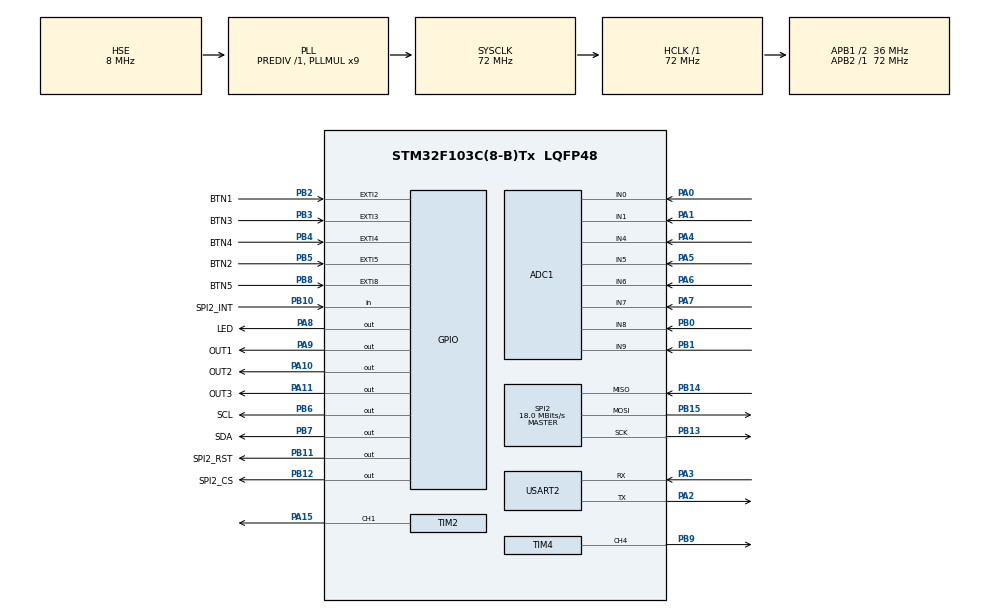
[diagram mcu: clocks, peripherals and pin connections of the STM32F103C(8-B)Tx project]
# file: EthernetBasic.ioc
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ADC1.Channel-0\#ChannelRegularConversion=ADC_CHANNEL_0
ADC1.Channel-1\#ChannelRegularConversion=ADC_CHANNEL_1
ADC1.Channel-2\#ChannelRegularConversion=ADC_CHANNEL_4
ADC1.Channel-3\#ChannelRegularConversion=ADC_CHANNEL_5
ADC1.Channel-4\#ChannelRegularConversion=ADC_CHANNEL_6
ADC1.Channel-5\#ChannelRegularConversion=ADC_CHANNEL_7
ADC1.Channel-6\#ChannelRegularConversion=ADC_CHANNEL_8
ADC1.Channel-7\#ChannelRegularConversion=ADC_CHANNEL_9
ADC1.ContinuousConvMode=DISABLE
ADC1.ExternalTrigConv=ADC_EXTERNALTRIGCONV_T3_TRGO
ADC1.NbrOfConversion=8
ADC1.NbrOfConversionFlag=1
ADC1.Rank-0\#ChannelRegularConversion=1
ADC1.Rank-1\#ChannelRegularConversion=2
ADC1.Rank-2\#ChannelRegularConversion=3
ADC1.Rank-3\#ChannelRegularConversion=4
ADC1.Rank-4\#ChannelRegularConversion=5
ADC1.Rank-5\#ChannelRegularConversion=6
ADC1.Rank-6\#ChannelRegularConversion=7
ADC1.Rank-7\#ChannelRegularConversion=8
ADC1.SamplingTime-0\#ChannelRegularConversion=ADC_SAMPLETIME_7CYCLES_5
ADC1.SamplingTime-1\#ChannelRegularConversion=ADC_SAMPLETIME_7CYCLES_5
ADC1.SamplingTime-2\#ChannelRegularConversion=ADC_SAMPLETIME_7CYCLES_5
ADC1.SamplingTime-3\#ChannelRegularConversion=ADC_SAMPLETIME_7CYCLES_5
ADC1.SamplingTime-4\#ChannelRegularConversion=ADC_SAMPLETIME_7CYCLES_5
ADC1.SamplingTime-5\#ChannelRegularConversion=ADC_SAMPLETIME_7CYCLES_5
ADC1.SamplingTime-6\#ChannelRegularConversion=ADC_SAMPLETIME_7CYCLES_5
ADC1.SamplingTime-7\#ChannelRegularConversion=ADC_SAMPLETIME_7CYCLES_5
ADC1.master=1
Dma.ADC1.0.Direction=DMA_PERIPH_TO_MEMORY
Dma.ADC1.0.Instance=DMA1_Channel1
Dma.ADC1.0.MemDataAlignment=DMA_MDATAALIGN_HALFWORD
Dma.ADC1.0.MemInc=DMA_MINC_ENABLE
Dma.ADC1.0.Mode=DMA_CIRCULAR
Dma.ADC1.0.PeriphDataAlignment=DMA_PDATAALIGN_HALFWORD
Dma.ADC1.0.PeriphInc=DMA_PINC_DISABLE
Dma.ADC1.0.Priority=DMA_PRIORITY_LOW
Dma.Request0=ADC1
Mcu.Family=STM32F1
Mcu.Name=STM32F103C(8-B)Tx
Mcu.Package=LQFP48
NVIC.DMA1_Channel1_IRQn=true\:0\:0\:false\:false\:true\:false\:true\:true
NVIC.EXTI2_IRQn=true\:0\:0\:false\:false\:true\:true\:true\:true
NVIC.EXTI3_IRQn=true\:0\:0\:false\:false\:true\:true\:true\:true
NVIC.EXTI4_IRQn=true\:0\:0\:false\:false\:true\:true\:true\:true
NVIC.EXTI9_5_IRQn=true\:0\:0\:false\:false\:true\:true\:true\:true
NVIC.PriorityGroup=NVIC_PRIORITYGROUP_4
PA0-WKUP.Signal=ADCx_IN0
PA1.Signal=ADCx_IN1
PA10.GPIO_Label=OUT2
PA10.Signal=GPIO_Output
PA11.GPIO_Label=OUT3
PA11.Signal=GPIO_Output
PA13.Mode=Serial_Wire
PA13.Signal=SYS_JTMS-SWDIO
PA14.Mode=Serial_Wire
PA14.Signal=SYS_JTCK-SWCLK
PA15.Signal=S_TIM2_CH1_ETR
PA2.Mode=Asynchronous
PA2.Signal=USART2_TX
PA3.Mode=Asynchronous
PA3.Signal=USART2_RX
PA4.Signal=ADCx_IN4
PA5.Signal=ADCx_IN5
PA6.Signal=ADCx_IN6
PA7.Signal=ADCx_IN7
PA8.GPIO_Label=LED
PA8.Signal=GPIO_Output
PA9.GPIO_Label=OUT1
PA9.Signal=GPIO_Output
PB0.Signal=ADCx_IN8
PB1.Signal=ADCx_IN9
PB10.GPIO_Label=SPI2_INT
PB10.GPIO_PuPd=GPIO_PULLUP
PB10.Signal=GPIO_Input
PB11.GPIO_Label=SPI2_RST
PB11.GPIO_PuPd=GPIO_PULLUP
PB11.GPIO_Speed=GPIO_SPEED_FREQ_HIGH
PB11.Signal=GPIO_Output
PB12.GPIO_Label=SPI2_CS
PB12.GPIO_PuPd=GPIO_PULLUP
PB12.GPIO_Speed=GPIO_SPEED_FREQ_HIGH
PB12.Signal=GPIO_Output
PB13.Mode=Full_Duplex_Master
PB13.Signal=SPI2_SCK
PB14.Mode=Full_Duplex_Master
PB14.Signal=SPI2_MISO
PB15.Mode=Full_Duplex_Master
PB15.Signal=SPI2_MOSI
PB2.GPIO_Label=BTN1
PB2.GPIO_ModeDefaultEXTI=GPIO_MODE_IT_FALLING
PB2.GPIO_PuPd=GPIO_NOPULL
PB2.Signal=GPXTI2
PB3.GPIO_Label=BTN3
PB3.GPIO_ModeDefaultEXTI=GPIO_MODE_IT_FALLING
PB3.Signal=GPXTI3
PB4.GPIO_Label=BTN4
PB4.GPIO_ModeDefaultEXTI=GPIO_MODE_IT_FALLING
PB4.Signal=GPXTI4
PB5.GPIO_Label=BTN2
PB5.GPIO_ModeDefaultEXTI=GPIO_MODE_IT_FALLING
PB5.GPIO_PuPd=GPIO_NOPULL
PB5.Signal=GPXTI5
PB6.GPIO_Label=SCL
PB6.GPIO_ModeDefaultOutputPP=GPIO_MODE_OUTPUT_OD
PB6.GPIO_PuPd=GPIO_PULLUP
PB6.GPIO_Speed=GPIO_SPEED_FREQ_HIGH
PB6.PinState=GPIO_PIN_SET
PB6.Signal=GPIO_Output
PB7.GPIO_Label=SDA
PB7.GPIO_ModeDefaultOutputPP=GPIO_MODE_OUTPUT_OD
PB7.GPIO_PuPd=GPIO_PULLUP
PB7.GPIO_Speed=GPIO_SPEED_FREQ_HIGH
PB7.PinState=GPIO_PIN_SET
PB7.Signal=GPIO_Output
PB8.GPIO_Label=BTN5
PB8.GPIO_ModeDefaultEXTI=GPIO_MODE_IT_FALLING
PB8.Signal=GPXTI8
PB9.Signal=S_TIM4_CH4
PC14-OSC32_IN.Mode=LSE-External-Oscillator
PC14-OSC32_IN.Signal=RCC_OSC32_IN
PC15-OSC32_OUT.Mode=LSE-External-Oscillator
PC15-OSC32_OUT.Signal=RCC_OSC32_OUT
PD0-OSC_IN.Mode=HSE-External-Oscillator
PD0-OSC_IN.Signal=RCC_OSC_IN
PD1-OSC_OUT.Mode=HSE-External-Oscillator
PD1-OSC_OUT.Signal=RCC_OSC_OUT
ProjectManager.HeapSize=0x200
ProjectManager.StackSize=0x400
ProjectManager.TargetToolchain=MDK-ARM V5.32
RCC.ADCPresc=RCC_ADCPCLK2_DIV6
RCC.AHBFreq_Value=72000000
RCC.APB1CLKDivider=RCC_HCLK_DIV2
RCC.APB1Freq_Value=36000000
RCC.APB1TimFreq_Value=72000000
RCC.APB2Freq_Value=72000000
RCC.APB2TimFreq_Value=72000000
RCC.HCLKFreq_Value=72000000
RCC.PLLMUL=RCC_PLL_MUL9
RCC.PLLSourceVirtual=RCC_PLLSOURCE_HSE
RCC.SYSCLKFreq_VALUE=72000000
RCC.SYSCLKSource=RCC_SYSCLKSOURCE_PLLCLK
RCC.USBFreq_Value=72000000
SH.ADCx_IN0.0=ADC1_IN0,IN0
SH.ADCx_IN1.0=ADC1_IN1,IN1
SH.ADCx_IN4.0=ADC1_IN4,IN4
SH.ADCx_IN5.0=ADC1_IN5,IN5
SH.ADCx_IN6.0=ADC1_IN6,IN6
SH.ADCx_IN7.0=ADC1_IN7,IN7
SH.ADCx_IN8.0=ADC1_IN8,IN8
SH.ADCx_IN9.0=ADC1_IN9,IN9
SH.S_TIM2_CH1_ETR.0=TIM2_CH1,PWM Generation1 CH1
SH.S_TIM4_CH4.0=TIM4_CH4,PWM Generation4 CH4
SPI2.CalculateBaudRate=18.0 MBits/s
SPI2.Direction=SPI_DIRECTION_2LINES
SPI2.Mode=SPI_MODE_MASTER
SPI2.VirtualType=VM_MASTER
TIM1.Period=34560 - 1
TIM1.Prescaler=65536 - 1
TIM2.Channel-PWM\ Generation1\ CH1=TIM_CHANNEL_1
TIM2.Period=100 - 1
TIM2.Prescaler=72 - 1
TIM2.Pulse-PWM\ Generation1\ CH1=50
TIM3.Period=2880 - 1
TIM3.Prescaler=65536 - 1
TIM3.TIM_MasterOutputTrigger=TIM_TRGO_UPDATE
TIM4.Channel-PWM\ Generation4\ CH4=TIM_CHANNEL_4
TIM4.Period=100 - 1
TIM4.Prescaler=72 - 1
TIM4.Pulse-PWM\ Generation4\ CH4=50
USART2.VirtualMode=VM_ASYNC
VP_TIM1_VS_ClockSourceINT.Mode=Internal
VP_TIM2_VS_ClockSourceINT.Mode=Internal
VP_TIM3_VS_ClockSourceINT.Mode=Internal
VP_TIM4_VS_ClockSourceINT.Mode=Internal
board=custom

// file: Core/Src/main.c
/* USER CODE BEGIN Header */
/**
  ******************************************************************************
  * @file           : main.c
  * @brief          : Main program body
  ******************************************************************************
  * @attention
  *
  * Copyright (c) 2025 STMicroelectronics.
  * All rights reserved.
  *
  * This software is licensed under terms that can be found in the LICENSE file
  * in the root directory of this software component.
  * If no LICENSE file comes with this software, it is provided AS-IS.
  *
  ******************************************************************************
  */
/* USER CODE END Header */
#include "main.h"
#include "adc.h"
#include "dma.h"
#include "spi.h"
#include "tim.h"
#include "usart.h"
#include "gpio.h"

/* USER CODE BEGIN PV */
uint16_t dataBuf[8];
uint8_t string[16];

extern uint8_t call_name, data_type;
/* USER CODE END PV */

void SystemClock_Config(void);

int main(void)
{

  /* MCU Configuration--------------------------------------------------------*/

  /* Reset of all peripherals, Initializes the Flash interface and the Systick. */
  HAL_Init();

  /* Configure the system clock */
  SystemClock_Config();

  /* Initialize all configured peripherals */
  MX_GPIO_Init();
  MX_DMA_Init();
  MX_SPI2_Init();
  MX_USART2_UART_Init();
  MX_ADC1_Init();
  MX_TIM3_Init();
  MX_TIM1_Init();
  MX_TIM2_Init();
  MX_TIM4_Init();
  /* USER CODE BEGIN 2 */
  system_init();
  HAL_TIM_Base_Start(&htim1);
  TIM1->CNT = 0;

  HAL_ADC_Start_DMA(&hadc1, (uint32_t *)&dataBuf, 8);
  HAL_TIM_Base_Start(&htim3);

  OLED_Init();
  OLED_Clear();
  sprintf((char *)string, "No:%3d, CH:%3d", call_name, data_type);
  OLED_ShowString(0, 0, string, 16, 1);
//  OLED_ShowString(0, 2, (uint8_t *)"Developer", 16, 1);
  /* USER CODE END 2 */

  /* Infinite loop */
  while (1)
  {

    /* USER CODE BEGIN 3 */
    system_run();
  }
  /* USER CODE END 3 */
}

void SystemClock_Config(void)
{
  RCC_OscInitTypeDef RCC_OscInitStruct = {0};
  RCC_ClkInitTypeDef RCC_ClkInitStruct = {0};
  RCC_PeriphCLKInitTypeDef PeriphClkInit = {0};

  /** Initializes the RCC Oscillators according to the specified parameters
  * in the RCC_OscInitTypeDef structure.
  */
  RCC_OscInitStruct.OscillatorType = RCC_OSCILLATORTYPE_HSE;
  RCC_OscInitStruct.HSEState = RCC_HSE_ON;
  RCC_OscInitStruct.HSEPredivValue = RCC_HSE_PREDIV_DIV1;
  RCC_OscInitStruct.HSIState = RCC_HSI_ON;
  RCC_OscInitStruct.PLL.PLLState = RCC_PLL_ON;
  RCC_OscInitStruct.PLL.PLLSource = RCC_PLLSOURCE_HSE;
  RCC_OscInitStruct.PLL.PLLMUL = RCC_PLL_MUL9;
  if (HAL_RCC_OscConfig(&RCC_OscInitStruct) != HAL_OK)
  {
    Error_Handler();
  }

  /** Initializes the CPU, AHB and APB buses clocks
  */
  RCC_ClkInitStruct.ClockType = RCC_CLOCKTYPE_HCLK|RCC_CLOCKTYPE_SYSCLK
                              |RCC_CLOCKTYPE_PCLK1|RCC_CLOCKTYPE_PCLK2;
  RCC_ClkInitStruct.SYSCLKSource = RCC_SYSCLKSOURCE_PLLCLK;
  RCC_ClkInitStruct.AHBCLKDivider = RCC_SYSCLK_DIV1;
  RCC_ClkInitStruct.APB1CLKDivider = RCC_HCLK_DIV2;
  RCC_ClkInitStruct.APB2CLKDivider = RCC_HCLK_DIV1;

  if (HAL_RCC_ClockConfig(&RCC_ClkInitStruct, FLASH_LATENCY_2) != HAL_OK)
  {
    Error_Handler();
  }
  PeriphClkInit.PeriphClockSelection = RCC_PERIPHCLK_ADC;
  PeriphClkInit.AdcClockSelection = RCC_ADCPCLK2_DIV6;
  if (HAL_RCCEx_PeriphCLKConfig(&PeriphClkInit) != HAL_OK)
  {
    Error_Handler();
  }
}

/* USER CODE BEGIN 4 */
//void HAL_ADC_ConvCpltCallback(ADC_HandleTypeDef *hadc)
//{
//  uint32_t val = 0;
//  val = 1;
//}
/* USER CODE END 4 */

void Error_Handler(void)
{
  __disable_irq();
  while (1)
  {
  }
}
